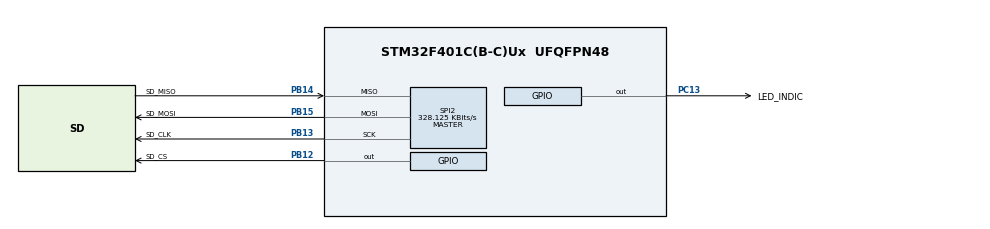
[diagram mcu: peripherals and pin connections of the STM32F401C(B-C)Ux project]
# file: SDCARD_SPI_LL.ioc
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Dma.Request0=SPI2_RX
Dma.Request1=SPI2_TX
Dma.SPI2_RX.0.Direction=DMA_PERIPH_TO_MEMORY
Dma.SPI2_RX.0.FIFOMode=DMA_FIFOMODE_DISABLE
Dma.SPI2_RX.0.Instance=DMA1_Stream3
Dma.SPI2_RX.0.MemDataAlignment=DMA_MDATAALIGN_BYTE
Dma.SPI2_RX.0.MemInc=DMA_MINC_ENABLE
Dma.SPI2_RX.0.Mode=DMA_NORMAL
Dma.SPI2_RX.0.PeriphDataAlignment=DMA_PDATAALIGN_BYTE
Dma.SPI2_RX.0.PeriphInc=DMA_PINC_DISABLE
Dma.SPI2_RX.0.Priority=DMA_PRIORITY_LOW
Dma.SPI2_TX.1.Direction=DMA_MEMORY_TO_PERIPH
Dma.SPI2_TX.1.FIFOMode=DMA_FIFOMODE_DISABLE
Dma.SPI2_TX.1.Instance=DMA1_Stream4
Dma.SPI2_TX.1.MemDataAlignment=DMA_MDATAALIGN_BYTE
Dma.SPI2_TX.1.MemInc=DMA_MINC_ENABLE
Dma.SPI2_TX.1.Mode=DMA_NORMAL
Dma.SPI2_TX.1.PeriphDataAlignment=DMA_PDATAALIGN_BYTE
Dma.SPI2_TX.1.PeriphInc=DMA_PINC_DISABLE
Dma.SPI2_TX.1.Priority=DMA_PRIORITY_LOW
FATFS._FS_LOCK=0
FATFS._USE_LFN=1
Mcu.Family=STM32F4
Mcu.Name=STM32F401C(B-C)Ux
Mcu.Package=UFQFPN48
NVIC.DMA1_Stream3_IRQn=true\:0\:0\:false\:false\:true\:false\:true\:true
NVIC.DMA1_Stream4_IRQn=true\:0\:0\:false\:false\:true\:false\:true\:true
NVIC.PriorityGroup=NVIC_PRIORITYGROUP_4
PA13.Mode=Serial_Wire
PA13.Signal=SYS_JTMS-SWDIO
PA14.Mode=Serial_Wire
PA14.Signal=SYS_JTCK-SWCLK
PB12.GPIO_Label=SD_CS
PB12.Signal=GPIO_Output
PB13.GPIO_Label=SD_CLK
PB13.Mode=Full_Duplex_Master
PB13.Signal=SPI2_SCK
PB14.GPIO_Label=SD_MISO
PB14.Mode=Full_Duplex_Master
PB14.Signal=SPI2_MISO
PB15.GPIO_Label=SD_MOSI
PB15.Mode=Full_Duplex_Master
PB15.Signal=SPI2_MOSI
PC13-ANTI_TAMP.GPIO_Label=LED_INDIC
PC13-ANTI_TAMP.Signal=GPIO_Output
PH0\ -\ OSC_IN.Mode=HSE-External-Oscillator
PH0\ -\ OSC_IN.Signal=RCC_OSC_IN
PH1\ -\ OSC_OUT.Mode=HSE-External-Oscillator
PH1\ -\ OSC_OUT.Signal=RCC_OSC_OUT
ProjectManager.HeapSize=0x200
ProjectManager.StackSize=0x400
ProjectManager.TargetToolchain=STM32CubeIDE
RCC.48MHZClocksFreq_Value=42000000
RCC.AHBFreq_Value=84000000
RCC.APB1CLKDivider=RCC_HCLK_DIV2
RCC.APB1Freq_Value=42000000
RCC.APB1TimFreq_Value=84000000
RCC.APB2Freq_Value=84000000
RCC.APB2TimFreq_Value=84000000
RCC.CortexFreq_Value=84000000
RCC.HCLKFreq_Value=84000000
RCC.HSE_VALUE=25000000
RCC.HSI_VALUE=16000000
RCC.LSE_VALUE=32768
RCC.PLLM=25
RCC.PLLN=168
RCC.PLLSourceVirtual=RCC_PLLSOURCE_HSE
RCC.SYSCLKFreq_VALUE=84000000
RCC.SYSCLKSource=RCC_SYSCLKSOURCE_PLLCLK
RCC.VCOOutputFreq_Value=168000000
SPI2.BaudRatePrescaler=SPI_BAUDRATEPRESCALER_128
SPI2.CalculateBaudRate=328.125 KBits/s
SPI2.Direction=SPI_DIRECTION_2LINES
SPI2.Mode=SPI_MODE_MASTER
SPI2.VirtualType=VM_MASTER
VP_FATFS_VS_Generic.Mode=User_defined
board=custom

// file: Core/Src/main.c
/* USER CODE BEGIN Header */
/**
  ******************************************************************************
  * @file           : main.c
  * @brief          : Main program body
  ******************************************************************************
  * @attention
  *
  * Copyright (c) 2025 STMicroelectronics.
  * All rights reserved.
  *
  * This software is licensed under terms that can be found in the LICENSE file
  * in the root directory of this software component.
  * If no LICENSE file comes with this software, it is provided AS-IS.
  *
  ******************************************************************************
  */
/* USER CODE END Header */
#include "main.h"
#include "fatfs.h"

void SystemClock_Config(void);
static void MX_GPIO_Init(void);
static void MX_DMA_Init(void);
static void MX_SPI2_Init(void);

int main(void)
{

  /* MCU Configuration--------------------------------------------------------*/

  /* Reset of all peripherals, Initializes the Flash interface and the Systick. */
  HAL_Init();

  /* Configure the system clock */
  SystemClock_Config();

  /* Initialize all configured peripherals */
  MX_GPIO_Init();
  MX_DMA_Init();
  MX_SPI2_Init();
  MX_FATFS_Init();
  /* USER CODE BEGIN 2 */
  (void)f_mount(&USERFatFS, USERPath, 0);

  if (f_open(&USERFile, "video.txt", FA_READ) != FR_OK)
  {
	  while (1)
	  {
		  LL_GPIO_TogglePin(LED_INDIC_GPIO_Port, LED_INDIC_Pin);
		  LL_mDelay(1000);
	  }
  }
  f_close(&USERFile);
  while (1)
  {
	  LL_GPIO_TogglePin(LED_INDIC_GPIO_Port, LED_INDIC_Pin);
	  LL_mDelay(100);
  }
  /* USER CODE END 2 */

  /* Infinite loop */
  while (1)
  {

  }
}

void SystemClock_Config(void)
{
  LL_FLASH_SetLatency(LL_FLASH_LATENCY_2);
  while(LL_FLASH_GetLatency()!= LL_FLASH_LATENCY_2)
  {
  }
  LL_PWR_SetRegulVoltageScaling(LL_PWR_REGU_VOLTAGE_SCALE2);
  LL_RCC_HSE_Enable();

   /* Wait till HSE is ready */
  while(LL_RCC_HSE_IsReady() != 1)
  {

  }
  LL_RCC_PLL_ConfigDomain_SYS(LL_RCC_PLLSOURCE_HSE, LL_RCC_PLLM_DIV_25, 168, LL_RCC_PLLP_DIV_2);
  LL_RCC_PLL_Enable();

   /* Wait till PLL is ready */
  while(LL_RCC_PLL_IsReady() != 1)
  {

  }
  while (LL_PWR_IsActiveFlag_VOS() == 0)
  {
  }
  LL_RCC_SetAHBPrescaler(LL_RCC_SYSCLK_DIV_1);
  LL_RCC_SetAPB1Prescaler(LL_RCC_APB1_DIV_2);
  LL_RCC_SetAPB2Prescaler(LL_RCC_APB2_DIV_1);
  LL_RCC_SetSysClkSource(LL_RCC_SYS_CLKSOURCE_PLL);

   /* Wait till System clock is ready */
  while(LL_RCC_GetSysClkSource() != LL_RCC_SYS_CLKSOURCE_STATUS_PLL)
  {

  }
  LL_SetSystemCoreClock(84000000);

   /* Update the time base */
  if (HAL_InitTick (TICK_INT_PRIORITY) != HAL_OK)
  {
    Error_Handler();
  }
  LL_RCC_SetTIMPrescaler(LL_RCC_TIM_PRESCALER_TWICE);
}

static void MX_SPI2_Init(void)
{

  LL_SPI_InitTypeDef SPI_InitStruct = {0};

  LL_GPIO_InitTypeDef GPIO_InitStruct = {0};

  /* Peripheral clock enable */
  LL_APB1_GRP1_EnableClock(LL_APB1_GRP1_PERIPH_SPI2);

  LL_AHB1_GRP1_EnableClock(LL_AHB1_GRP1_PERIPH_GPIOB);
  /**SPI2 GPIO Configuration
  PB13   ------> SPI2_SCK
  PB14   ------> SPI2_MISO
  PB15   ------> SPI2_MOSI
  */
  GPIO_InitStruct.Pin = SD_CLK_Pin|SD_MISO_Pin|SD_MOSI_Pin;
  GPIO_InitStruct.Mode = LL_GPIO_MODE_ALTERNATE;
  GPIO_InitStruct.Speed = LL_GPIO_SPEED_FREQ_VERY_HIGH;
  GPIO_InitStruct.OutputType = LL_GPIO_OUTPUT_PUSHPULL;
  GPIO_InitStruct.Pull = LL_GPIO_PULL_NO;
  GPIO_InitStruct.Alternate = LL_GPIO_AF_5;
  LL_GPIO_Init(GPIOB, &GPIO_InitStruct);

  /* SPI2 DMA Init */

  /* SPI2_RX Init */
  LL_DMA_SetChannelSelection(DMA1, LL_DMA_STREAM_3, LL_DMA_CHANNEL_0);

  LL_DMA_SetDataTransferDirection(DMA1, LL_DMA_STREAM_3, LL_DMA_DIRECTION_PERIPH_TO_MEMORY);

  LL_DMA_SetStreamPriorityLevel(DMA1, LL_DMA_STREAM_3, LL_DMA_PRIORITY_LOW);

  LL_DMA_SetMode(DMA1, LL_DMA_STREAM_3, LL_DMA_MODE_NORMAL);

  LL_DMA_SetPeriphIncMode(DMA1, LL_DMA_STREAM_3, LL_DMA_PERIPH_NOINCREMENT);

  LL_DMA_SetMemoryIncMode(DMA1, LL_DMA_STREAM_3, LL_DMA_MEMORY_INCREMENT);

  LL_DMA_SetPeriphSize(DMA1, LL_DMA_STREAM_3, LL_DMA_PDATAALIGN_BYTE);

  LL_DMA_SetMemorySize(DMA1, LL_DMA_STREAM_3, LL_DMA_MDATAALIGN_BYTE);

  LL_DMA_DisableFifoMode(DMA1, LL_DMA_STREAM_3);

  /* SPI2_TX Init */
  LL_DMA_SetChannelSelection(DMA1, LL_DMA_STREAM_4, LL_DMA_CHANNEL_0);

  LL_DMA_SetDataTransferDirection(DMA1, LL_DMA_STREAM_4, LL_DMA_DIRECTION_MEMORY_TO_PERIPH);

  LL_DMA_SetStreamPriorityLevel(DMA1, LL_DMA_STREAM_4, LL_DMA_PRIORITY_LOW);

  LL_DMA_SetMode(DMA1, LL_DMA_STREAM_4, LL_DMA_MODE_NORMAL);

  LL_DMA_SetPeriphIncMode(DMA1, LL_DMA_STREAM_4, LL_DMA_PERIPH_NOINCREMENT);

  LL_DMA_SetMemoryIncMode(DMA1, LL_DMA_STREAM_4, LL_DMA_MEMORY_INCREMENT);

  LL_DMA_SetPeriphSize(DMA1, LL_DMA_STREAM_4, LL_DMA_PDATAALIGN_BYTE);

  LL_DMA_SetMemorySize(DMA1, LL_DMA_STREAM_4, LL_DMA_MDATAALIGN_BYTE);

  LL_DMA_DisableFifoMode(DMA1, LL_DMA_STREAM_4);

  /* SPI2 parameter configuration*/
  SPI_InitStruct.TransferDirection = LL_SPI_FULL_DUPLEX;
  SPI_InitStruct.Mode = LL_SPI_MODE_MASTER;
  SPI_InitStruct.DataWidth = LL_SPI_DATAWIDTH_8BIT;
  SPI_InitStruct.ClockPolarity = LL_SPI_POLARITY_LOW;
  SPI_InitStruct.ClockPhase = LL_SPI_PHASE_1EDGE;
  SPI_InitStruct.NSS = LL_SPI_NSS_SOFT;
  SPI_InitStruct.BaudRate = LL_SPI_BAUDRATEPRESCALER_DIV128;
  SPI_InitStruct.BitOrder = LL_SPI_MSB_FIRST;
  SPI_InitStruct.CRCCalculation = LL_SPI_CRCCALCULATION_DISABLE;
  SPI_InitStruct.CRCPoly = 10;
  LL_SPI_Init(SPI2, &SPI_InitStruct);
  LL_SPI_SetStandard(SPI2, LL_SPI_PROTOCOL_MOTOROLA);

}

static void MX_DMA_Init(void)
{

  /* Init with LL driver */
  /* DMA controller clock enable */
  LL_AHB1_GRP1_EnableClock(LL_AHB1_GRP1_PERIPH_DMA1);

  /* DMA interrupt init */
  /* DMA1_Stream3_IRQn interrupt configuration */
  NVIC_SetPriority(DMA1_Stream3_IRQn, NVIC_EncodePriority(NVIC_GetPriorityGrouping(),0, 0));
  NVIC_EnableIRQ(DMA1_Stream3_IRQn);
  /* DMA1_Stream4_IRQn interrupt configuration */
  NVIC_SetPriority(DMA1_Stream4_IRQn, NVIC_EncodePriority(NVIC_GetPriorityGrouping(),0, 0));
  NVIC_EnableIRQ(DMA1_Stream4_IRQn);

}

static void MX_GPIO_Init(void)
{
  LL_GPIO_InitTypeDef GPIO_InitStruct = {0};

  /* GPIO Ports Clock Enable */
  LL_AHB1_GRP1_EnableClock(LL_AHB1_GRP1_PERIPH_GPIOC);
  LL_AHB1_GRP1_EnableClock(LL_AHB1_GRP1_PERIPH_GPIOH);
  LL_AHB1_GRP1_EnableClock(LL_AHB1_GRP1_PERIPH_GPIOB);
  LL_AHB1_GRP1_EnableClock(LL_AHB1_GRP1_PERIPH_GPIOA);

  /**/
  LL_GPIO_ResetOutputPin(LED_INDIC_GPIO_Port, LED_INDIC_Pin);

  /**/
  LL_GPIO_ResetOutputPin(SD_CS_GPIO_Port, SD_CS_Pin);

  /**/
  GPIO_InitStruct.Pin = LED_INDIC_Pin;
  GPIO_InitStruct.Mode = LL_GPIO_MODE_OUTPUT;
  GPIO_InitStruct.Speed = LL_GPIO_SPEED_FREQ_LOW;
  GPIO_InitStruct.OutputType = LL_GPIO_OUTPUT_PUSHPULL;
  GPIO_InitStruct.Pull = LL_GPIO_PULL_NO;
  LL_GPIO_Init(LED_INDIC_GPIO_Port, &GPIO_InitStruct);

  /**/
  GPIO_InitStruct.Pin = SD_CS_Pin;
  GPIO_InitStruct.Mode = LL_GPIO_MODE_OUTPUT;
  GPIO_InitStruct.Speed = LL_GPIO_SPEED_FREQ_LOW;
  GPIO_InitStruct.OutputType = LL_GPIO_OUTPUT_PUSHPULL;
  GPIO_InitStruct.Pull = LL_GPIO_PULL_NO;
  LL_GPIO_Init(SD_CS_GPIO_Port, &GPIO_InitStruct);

}

void Error_Handler(void)
{
  __disable_irq();
  while (1)
  {
  }
}
